# psoc6_01 register map
Vendor: Infineon Technologies; Series: PSOC6_01; File version: 1.0
CPU: CM4 r0p1, little endian, MPU, FPU, VTOR, 3 interrupt priority bits
Registers are 32-bit, read-write, reset 0x0 unless marked. A register's access mark holds for its fields unless they carry their own. Offsets are from the block's base; [hi:lo] are bit positions; lines under a group give offsets from that group; {n}, {i} and the like mark numbered series.

## PASS — PASS top-level MMIO (DSABv2, INTR)
Base 0x411F0000
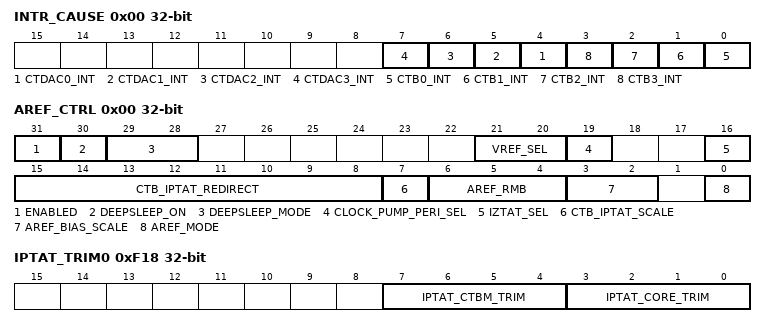
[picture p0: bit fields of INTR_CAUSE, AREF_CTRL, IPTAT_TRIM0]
0x00 INTR_CAUSE ro — Interrupt cause register
  [n+4] CTDAC{n}_INT (n=0..3) — CTDAC{n} interrupt pending
  [n] CTB{n}_INT (n=0..3) — CTB{n} interrupt pending
0xE00 AREF group — AREF configuration
  0x00 AREF_CTRL — global AREF control
    [31] ENABLED — Disable AREF
    [30] DEEPSLEEP_ON — - 0: AREF IP disabled/off during DeepSleep power mode - 1: AREF IP remains enabled during DeepSleep power mode (if ENABLED=1)
    [29:28] DEEPSLEEP_MODE — AREF DeepSleep Operation Modes (only applies if DEEPSLEEP_ON = 1)
      0=OFF (All blocks 'OFF' in DeepSleep); 1=IPTAT (IPTAT bias generator 'ON' in DeepSleep (used for fast AREF wakeup only: IPTAT outputs not available)); 2=IPTAT_IZTAT (IPTAT bias generator and outputs 'ON' in DeepSleep (used for biasing the CTBm with a PTAT current only in deep sleep) *Note that this mode also requires that the CTB_IPTAT_REDIRECT be set if the CTBm opamp is to operate in DeepSleep); 3=IPTAT_IZTAT_VREF (IPTAT, VREF, and IZTAT generators 'ON' in DeepSleep. This mode provides identical AREF functionality in DeepSleep as in the Active mode.)
    [21:20] VREF_SEL — bandgap voltage select control
      0=SRSS (Use 0.8V Vref from SRSS); 1=LOCAL (Use locally generated Vref); 2=EXTERNAL (Use externally supplied Vref (aref_ext_vref))
    [19] CLOCK_PUMP_PERI_SEL — CTBm charge pump clock source select. This field has nothing to do with the AREF. 0: Use the dedicated pump clock from SRSS (default) 1: Use one of the CLK_PERI dividers
    [16] IZTAT_SEL — iztat current select control
      0=SRSS (Use 250nA IZTAT from SRSS); 1=LOCAL (Use locally generated 250nA)
    [15:8] CTB_IPTAT_REDIRECT — Re-direct the CTB IPTAT output current. This can be used to reduce amplifier bias glitches during power mode transitions (for PSoC4A/B DSAB backwards compatibility). 0: Opamp<n>.IPTAT = AREF.IPTAT and Opamp<n>.IZTAT= AREF.IZTAT 1: Opamp<n>.IPTAT = HiZ and Opamp<n>.IZTAT= AREF.IPTAT *Note that in Deep Sleep, the AREF IZTAT and/or IPTAT currents can be disabled and therefore the corresponding Opamp<n>.IZTAT/IPTAT will be HiZ.
    [7] CTB_IPTAT_SCALE — CTB IPTAT current scaler. This bit must be set in order to operate the CTB amplifiers in the lowest power mode. This bit is chip-wide (controls all CTB amplifiers). 0: 1uA 1: 100nA
    [6:4] AREF_RMB — AREF control signals (RMB). Bit 0: Manual VBG startup circuit enable 0: normal VBG startup circuit operation 1: VBG startup circuit is forced 'always on' Bit 1: Manual disable of IPTAT2 DAC 0: normal IPTAT2 DAC operation 1: PTAT2 DAC is disabled while VBG startup is active Bit 2: Manual enable of VBG offset correction DAC 0: normal VBG offset correction DAC operation 1: VBG offset correction DAC is enabled while VBG startup is active
    [3:2] AREF_BIAS_SCALE — BIAS Current Control for all AREF Amplifiers. (These are risk mitigation bits that should not be touched by the customer: the impact on IDDA/noise/startup still needs to be characterized) 0: 125nA (reduced bias: reduction in total AREF IDDA, higher noise and longer startup times) 1: 250nA ('default' setting to meet bandgap performance (noise/startup) and IDDA specifications) 2: 375nA (increased bias: increase in total AREF IDDA, lower noise and shorter startup times) 3: 500nA (further increased bias: increase in total AREF IDDA, lower noise and shorter startup times)
    [0] AREF_MODE — Control bit to trade off AREF settling and noise performance
      0=NORMAL (Nominal noise normal startup mode (meets normal mode settling and noise specifications)); 1=FAST_START (High noise fast startup mode (meets fast mode settling and noise specifications))
0xF00 VREF_TRIM0 — VREF Trim bits
  [7:0] VREF_ABS_TRIM
0xF04 VREF_TRIM1 — VREF Trim bits
  [7:0] VREF_TEMPCO_TRIM
0xF08 VREF_TRIM2 — VREF Trim bits
  [7:0] VREF_CURV_TRIM
0xF0C VREF_TRIM3 — VREF Trim bits
  [3:0] VREF_ATTEN_TRIM — Obsolete
0xF10 IZTAT_TRIM0 — IZTAT Trim bits
  [7:0] IZTAT_ABS_TRIM
0xF14 IZTAT_TRIM1 — IZTAT Trim bits
  [7:0] IZTAT_TC_TRIM — IZTAT temperature correction trim (RMB) 0x00 : No IZTAT temperature correction 0xFF : Maximum IZTAT temperature correction As this is a Risk Mitigation Register, it should be loaded with 0x08.
0xF18 IPTAT_TRIM0 — IPTAT Trim bits
  [7:4] IPTAT_CTBM_TRIM — CTMB PTAT Current Trim 0x0 : Minimum CTMB IPTAT Current (~875nA) 0xF : Maximum CTMB IPTAT Current (~1.1uA)
  [3:0] IPTAT_CORE_TRIM — IPTAT trim 0x0 : Minimum IPTAT current (~150nA at room) 0xF : Maximum IPTAT current (~350nA at room)
0xF1C ICTAT_TRIM0 — ICTAT Trim bits
  [3:0] ICTAT_TRIM — ICTAT trim 0x00 : Minimum ICTAT current (~150nA at room) 0x0F : Maximum ICTAT current (~350nA at room)
